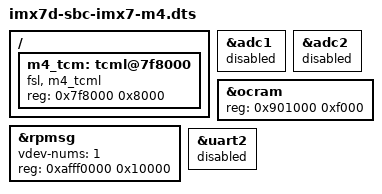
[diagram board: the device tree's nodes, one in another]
#include "imx7d-sbc-imx7.dts"

/ {
	m4_tcm: tcml@7f8000 {
		compatible = "fsl, m4_tcml";
		reg = <0x7f8000 0x8000>;
	};
};

&adc1 {
	status = "disabled";
};

&adc2 {
	status = "disabled";
};

&ocram {
	reg = <0x901000 0xf000>;
};

&rpmsg {
	vdev-nums = <1>;
	reg = <0xafff0000 0x10000>;
	status = "okay";
};

&uart2 {
	status = "disabled";
};

